# RZT2L register map
Vendor: Renesas Electronics Corporation; Series: RZT; File version: 1.20.00
CPU: other r0p0, little endian, MPU, no FPU, VTOR, 4 interrupt priority bits, 624 interrupts
Registers are 32-bit, read-write, reset 0x0 unless marked. A register's access mark holds for its fields unless they carry their own. Offsets are from the block's base; [hi:lo] are bit positions; {n}, {i} and the like mark numbered series; 'fields as' and 'values as' point back to an identical list.

## ELC — Evnet Link Controller
Base 0x80090010
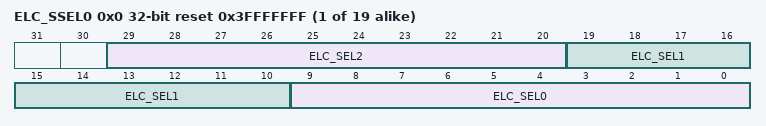
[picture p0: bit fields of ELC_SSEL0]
{0x0+4i} ELC_SSEL{i} (i=0..18) reset 0x3FFFFFFF — ELC Event Source Select Register {i}
  [29:20] ELC_SEL2 — Set the number for ELC event source to be linked to the ELC destination.
  [19:10] ELC_SEL1 — Set the number for ELC event source to be linked to the ELC destination.
  [9:0] ELC_SEL0 — Set the number for ELC event source to be linked to the ELC destination.

## DMA — DMAC Configuration
Base 0x80090060
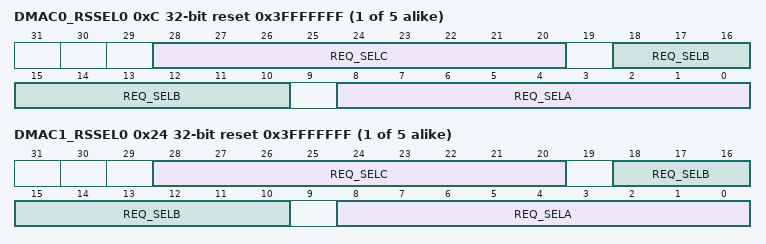
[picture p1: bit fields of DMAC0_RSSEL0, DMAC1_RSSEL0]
{0xC+4i} DMAC0_RSSEL{i} (i=0..4) reset 0x3FFFFFFF — DMAC Unit 0 Resource Select Register {i}
  [28:20] REQ_SELC — DMA Resource Select for Channel n + 2
  [18:10] REQ_SELB — DMA Resource Select for Channel n + 1
  [8:0] REQ_SELA — DMA Resource Select for Channel n
0x20 DMAC0_RSSEL5 reset 0x3FF — DMAC Unit 0 Resource Select Register 5
  [8:0] REQ_SELA — DMA Resource Select for Channel n
{0x24+4i} DMAC1_RSSEL{i} (i=0..4) reset 0x3FFFFFFF — DMAC Unit 1 Resource Select Register {i}
  fields as DMAC0_RSSEL0
0x38 DMAC1_RSSEL5 reset 0x3FF — DMAC Unit 1 Resource Select Register 5
  [8:0] REQ_SELA — DMA Resource Select for Channel n

## ETHSS — Ethernet Subsystem
Base 0x80110000
0x00 PRCMD — Ethernet Protect Register
0x08 MODCTRL — Mode Control Register
  [0] SW_MODE — Media I/F connectionSW_MODEMedia I/FPort 0Port 1Port 20ESC Port 0ESC Port 1GMAC Port1ESC Port 0ESC Port 1ESC Port 2
0x0C PTPMCTRL — PTP Mode Control Register
  [16] PTP_PLS_RSTn — Reset control for Pulse Generator (unit 0 - 3)
    0=Assert RESET; 1=Release RESET
0x14 PHYLNK reset 0x70 — Ethernet PHY Link Mode Register
  [6:4] CATLNK — Specify the active level of the ESC_PHYLINKn signal using the EtherCAT interface
    0=Active-Low PHYLINK signal; 1=Active-High PHYLINK signal
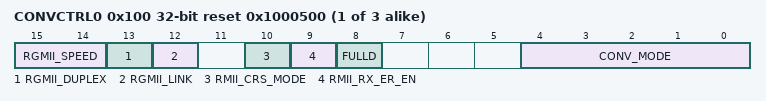
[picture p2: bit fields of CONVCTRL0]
{0x100+4i} CONVCTRL{i} (i=0..2) reset 0x1000500 — RGMII/RMII Converter {i} Control Register
  [15:14] RGMII_SPEED ro
    0=2.5 MHz; 1=25 MHz; 2=125 MHz
  [13] RGMII_DUPLEX ro
    0=Half-duplex; 1=Full-duplex
  [12] RGMII_LINK ro
    0=Down; 1=Up
  [10] RMII_CRS_MODE
    0=CRS | TX_EN; 1=CRS | TX_EN | RX_DV
  [9] RMII_RX_ER_EN
    0=RX_ER is always 0; 1=RX_ER signal
  [8] FULLD
    0=Half-duplex; 1=Full-duplex
  [4:0] CONV_MODE — Converter operation mode
0x114 CONVRST — RGMII/RMII Converter Reset Control Register
  [2:0] PHYIR
    0=Reset RGMII/RMII Converter; 1=Activate RGMII/RMII Converter

## ESC_INI — Initial Configuration 1 for EtherCAT Slave Controller
Base 0x80110200
0x00 ECATOFFADR — EtherCAT PHY Offset Address Setting Register
  [4:0] OADD — PHY Offset Address Setting
0x04 ECATOPMOD — EtherCAT Operation Mode Register
  [0] EEPROMSIZE — EEPROM Memory Size Specification
    0=16 Kbits or less; 1=32 Kbits to 4 Mbits
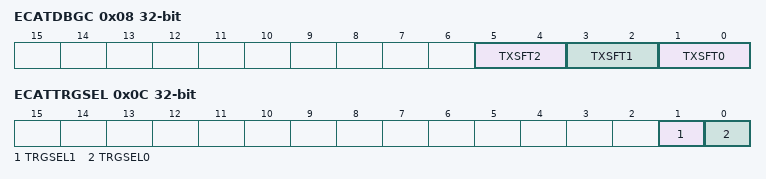
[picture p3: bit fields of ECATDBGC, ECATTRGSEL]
0x08 ECATDBGC — EtherCAT Debug Control Register
  [all] fields
    0=0 ns; 1=10 ns; 2=20 ns; 3=30 ns
  [5:4] TXSFT2 — Set the delay time for ETH2_TXC of the EtherCAT
  [3:2] TXSFT1 — Set the delay time for ETH1_TXC of the EtherCAT
  [1:0] TXSFT0 — Set the delay time for ETH0_TXC of the EtherCAT
0x0C ECATTRGSEL — EtherCAT DC Latch Trigger Select Register
  [1] TRGSEL1 — Select DC Latch Trigger 1 for ESC
    0=Select LATCH1 input from ELC; 1=Select LATCH1 input from external
  [0] TRGSEL0 — Select DC Latch Trigger 0 for ESC
    0=Select LATCH0 input from ELC; 1=Select LATCH0 input from external

## GMAC_PTP — GMAC for PTP
Base 0x80110400
{0x400+0x100*i} SWTMEN{i} (i=0..3) — PTP Timer Pulse Output Enable {i} Register
  [0] OUTEN — Enable GMAC_PTPOUTn Signal Output
    0=Disabled; 1=Enabled
{0x404+0x100*i} SWTMSTSEC{i} (i=0..3) — PTP Timer Pulse Start Second {i} Register
  [31:0] STSEC
{0x408+0x100*i} SWTMSTNS{i} (i=0..3) — PTP Timer Pulse Start Nanosecond {i} Register
  [31:0] STNS — Start Time by Nanosecond
{0x40C+0x100*i} SWTMPSEC{i} (i=0..3) — PTP Timer Pulse Period Second {i} Register
  [31:0] PSEC
{0x410+0x100*i} SWTMPNS{i} (i=0..3) reset 0x3B9ACA00 — PTP Timer Pulse Period Nanosecond {i} Register
  [31:0] PNS — Period by Nanosecond
{0x414+0x100*i} SWTMWTH{i} (i=0..3) reset 0x3 — PTP Timer Pulse Width {i} Register
  [15:0] WIDTH — Set the Pulse Width of GMAC_PTPOUTn in the cycle number of GMAC_PTP_REFCLK_I (8 ns).
{0x418+0x100*i} SWTMMAXP{i} (i=0..3) reset 0x3B9ACA00 — PTP Timer Pulse Max Nanosecond {i} Register
  [31:0] MAXP — Sets the boundary value in nanoseconds to carry from the nanosecond field to the second field. This register must be set to 0x3B9ACA00 (= 109) when TSCTRLSSR bit in Timestamp_Control register is set to 1. This register must be set to 0x80000000 (= 231) when TSCTRLSSR bit in Timestamp_Control register is reset to 0.
{0x41C+0x100*i} SWTMLATSEC{i} (i=0..3) — PTP Timer Pulse Latch Second {i} Register
  [31:0] LATSEC
{0x420+0x100*i} SWTMLATNS{i} (i=0..3) — PTP Timer Pulse Latch Nanosecond {i} Register
  [31:0] LATNS
